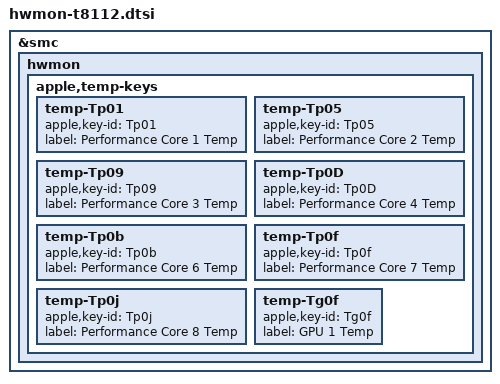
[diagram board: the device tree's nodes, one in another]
// SPDX-License-Identifier: GPL-2.0+ OR MIT
/*
 * t8112 specific hwmon sensors
 *
 * Copyright The Asahi Linux Contributors
 */

#include "hwmon-common.dtsi"

&smc {
	hwmon {
		apple,temp-keys {
			temp-Tp01 {
				apple,key-id = "Tp01";
				label = "Performance Core 1 Temp";
			};
			temp-Tp05 {
				apple,key-id = "Tp05";
				label = "Performance Core 2 Temp";
			};
			temp-Tp09 {
				apple,key-id = "Tp09";
				label = "Performance Core 3 Temp";
			};
			temp-Tp0D {
				apple,key-id = "Tp0D";
				label = "Performance Core 4 Temp";
			};
			temp-Tp0b {
				apple,key-id = "Tp0b";
				label = "Performance Core 6 Temp";
			};
			temp-Tp0f {
				apple,key-id = "Tp0f";
				label = "Performance Core 7 Temp";
			};
			temp-Tp0j {
				apple,key-id = "Tp0j";
				label = "Performance Core 8 Temp";
			};
			temp-Tg0f {
				apple,key-id = "Tg0f";
				label = "GPU 1 Temp";
			};
		};
	};
};
